# txchannel register map
Vendor: Texas Instruments
Peripheral module from a debugger description file (folder pktdma).
Registers are 32-bit, read-write, no defined reset value unless marked. A register's access mark holds for its fields unless they carry their own. Offsets are as the file gives them; lines under a group give offsets from that group; [hi:lo] are bit positions; {n}, {i} and the like mark numbered series; 'fields as' and 'values as' point back to an identical list; <NAME> marks a mode.

## PKTDMA_TXCHANNEL
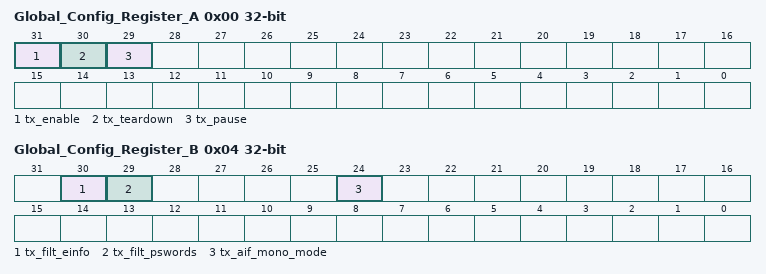
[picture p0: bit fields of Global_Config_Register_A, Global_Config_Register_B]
0x00 Global_Config_Register_A — Tx Channel Global Configuration Register A
  [31] tx_enable, [30] tx_teardown, [29] tx_pause
0x04 Global_Config_Register_B wo — Tx Channel Global Configuration Register B
  [30] tx_filt_einfo, [29] tx_filt_pswords, [24] tx_aif_mono_mode
